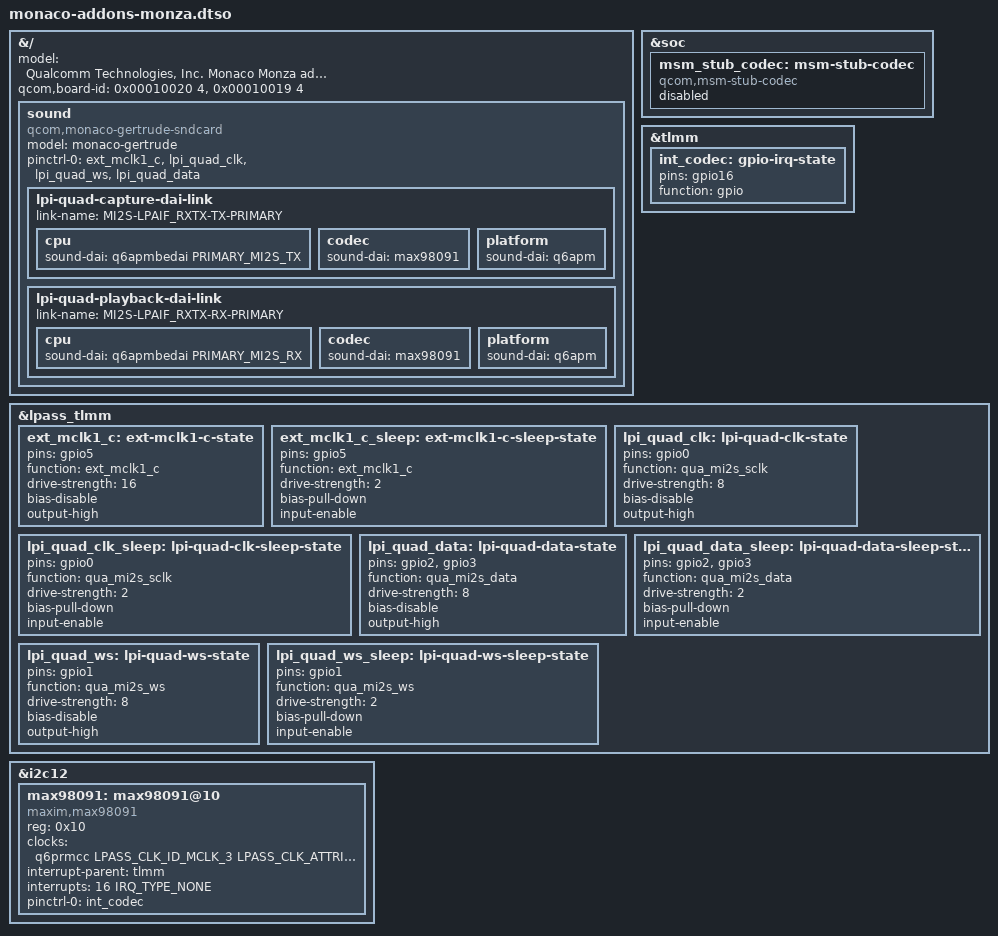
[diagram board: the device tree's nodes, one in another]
// SPDX-License-Identifier: BSD-3-Clause
/*
 * Copyright (c) Qualcomm Technologies, Inc. and/or its subsidiaries.
 */

/dts-v1/;
/plugin/;

#include "qcs8300-addons.dtsi"
#include "qcs8275-thermal-addons.dtsi"

&{/} {
	model = "Qualcomm Technologies, Inc. Monaco Monza addons";
	qcom,board-id = <0x00010020 4>, <0x00010019 4>;
	sound {
		compatible = "qcom,monaco-gertrude-sndcard";
		model = "monaco-gertrude";
		pinctrl-names = "default";
		pinctrl-0 = <&ext_mclk1_c>,<&lpi_quad_clk>,<&lpi_quad_ws>,<&lpi_quad_data>;

		lpi-quad-capture-dai-link {
			link-name = "MI2S-LPAIF_RXTX-TX-PRIMARY";

			cpu {
				sound-dai = <&q6apmbedai PRIMARY_MI2S_TX>;
			};

			codec {
				sound-dai = <&max98091>;
			};

			platform {
				sound-dai = <&q6apm>;
			};
		};

		lpi-quad-playback-dai-link {
			link-name = "MI2S-LPAIF_RXTX-RX-PRIMARY";

			cpu {
				sound-dai = <&q6apmbedai PRIMARY_MI2S_RX>;
			};

			codec {
				sound-dai = <&max98091>;
			};

			platform {
				sound-dai = <&q6apm>;
			};
		};
	};
};

&soc {
	msm_stub_codec: msm-stub-codec {
		compatible = "qcom,msm-stub-codec";
		#sound-dai-cells = <1>;
		status = "disabled";
	};
};

&tlmm {
	int_codec: gpio-irq-state {
		pins = "gpio16";
		function = "gpio";
	};
};

&lpass_tlmm {
	ext_mclk1_c: ext-mclk1-c-state {
		pins = "gpio5";
		function = "ext_mclk1_c";
		drive-strength = <16>;
		bias-disable;
		output-high;
	};

	ext_mclk1_c_sleep: ext-mclk1-c-sleep-state {
		pins = "gpio5";
		function = "ext_mclk1_c";
		drive-strength = <2>;
		bias-pull-down;
		input-enable;
	};

	lpi_quad_clk: lpi-quad-clk-state {
		pins = "gpio0";
		function = "qua_mi2s_sclk";
		drive-strength = <8>;
		bias-disable;
		output-high;
	};

	lpi_quad_clk_sleep: lpi-quad-clk-sleep-state {
		pins = "gpio0";
		function = "qua_mi2s_sclk";
		drive-strength = <2>;
		bias-pull-down;
		input-enable;
	};

	lpi_quad_data: lpi-quad-data-state {
		pins = "gpio2", "gpio3";
		function = "qua_mi2s_data";
		drive-strength = <8>;
		bias-disable;
		output-high;
	};

	lpi_quad_data_sleep: lpi-quad-data-sleep-state {
		pins = "gpio2", "gpio3";
		function = "qua_mi2s_data";
		drive-strength = <2>;
		bias-pull-down;
		input-enable;
	};

	lpi_quad_ws: lpi-quad-ws-state {
		pins = "gpio1";
		function = "qua_mi2s_ws";
		drive-strength = <8>;
		bias-disable;
		output-high;
	};

	lpi_quad_ws_sleep: lpi-quad-ws-sleep-state {
		pins = "gpio1";
		function = "qua_mi2s_ws";
		drive-strength = <2>;
		bias-pull-down;
		input-enable;
	};
};

&i2c12 {
	status = "okay";
	max98091: max98091@10 {
		compatible = "maxim,max98091";
		reg = <0x10>;
		#sound-dai-cells = <0>;
		clock-names = "mclk";
		clocks = <&q6prmcc LPASS_CLK_ID_MCLK_3 LPASS_CLK_ATTRIBUTE_COUPLE_NO>;
		interrupt-parent = <&tlmm>;
		interrupts = <16 IRQ_TYPE_NONE>;
		pinctrl-names = "default";
		pinctrl-0 = <&int_codec>;
	};
};
